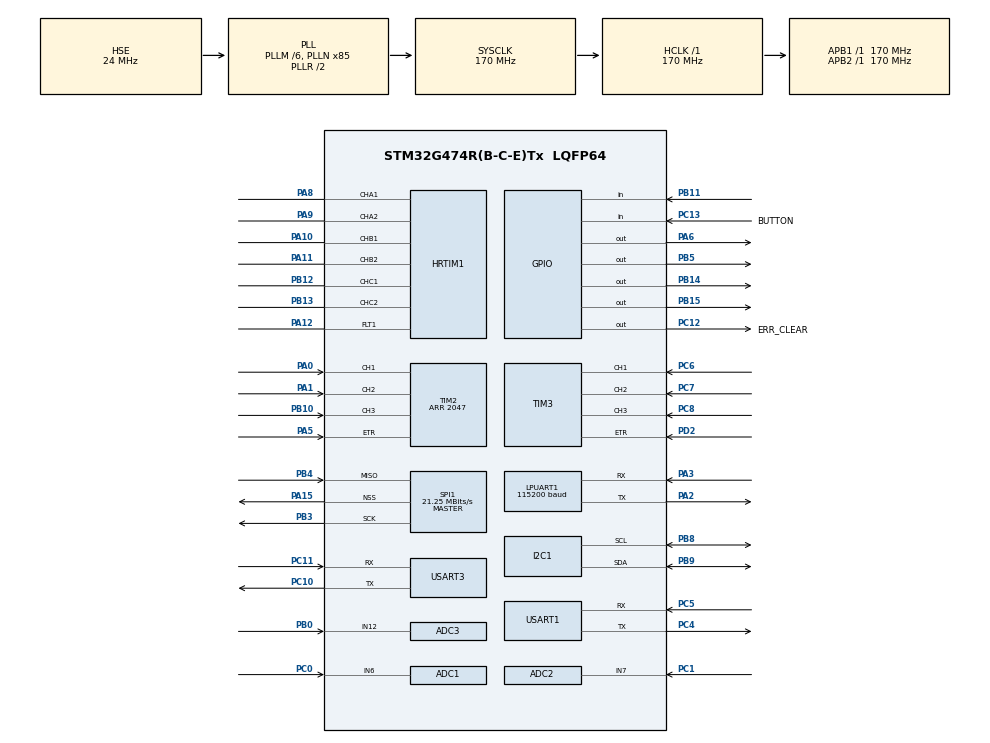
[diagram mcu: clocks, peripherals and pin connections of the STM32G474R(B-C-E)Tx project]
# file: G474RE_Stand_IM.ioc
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ADC1.Channel-0\#ChannelRegularConversion=ADC_CHANNEL_6
ADC1.DMAContinuousRequests=ENABLE
ADC1.ExternalTrigConv=ADC_EXTERNALTRIG_HRTIM_TRG1
ADC1.NbrOfConversionFlag=1
ADC1.Offset-0\#ChannelRegularConversion=2047
ADC1.OffsetNumber-0\#ChannelRegularConversion=ADC_OFFSET_1
ADC1.Rank-0\#ChannelRegularConversion=1
ADC1.SamplingTime-0\#ChannelRegularConversion=ADC_SAMPLETIME_47CYCLES_5
ADC1.master=1
ADC2.Channel-0\#ChannelRegularConversion=ADC_CHANNEL_7
ADC2.DMAContinuousRequests=ENABLE
ADC2.ExternalTrigConv=ADC_EXTERNALTRIG_HRTIM_TRG1
ADC2.NbrOfConversionFlag=1
ADC2.Offset-0\#ChannelRegularConversion=2047
ADC2.OffsetNumber-0\#ChannelRegularConversion=ADC_OFFSET_1
ADC2.Rank-0\#ChannelRegularConversion=1
ADC2.SamplingTime-0\#ChannelRegularConversion=ADC_SAMPLETIME_47CYCLES_5
ADC3.Channel-0\#ChannelRegularConversion=ADC_CHANNEL_12
ADC3.DMAContinuousRequests=ENABLE
ADC3.ExternalTrigConv=ADC_EXTERNALTRIG_HRTIM_TRG1
ADC3.NbrOfConversionFlag=1
ADC3.OffsetNumber-0\#ChannelRegularConversion=ADC_OFFSET_NONE
ADC3.Rank-0\#ChannelRegularConversion=1
ADC3.SamplingTime-0\#ChannelRegularConversion=ADC_SAMPLETIME_47CYCLES_5
ADC3.master=1
Dma.ADC1.0.Direction=DMA_PERIPH_TO_MEMORY
Dma.ADC1.0.EventEnable=DISABLE
Dma.ADC1.0.Instance=DMA1_Channel1
Dma.ADC1.0.MemDataAlignment=DMA_MDATAALIGN_HALFWORD
Dma.ADC1.0.MemInc=DMA_MINC_ENABLE
Dma.ADC1.0.Mode=DMA_CIRCULAR
Dma.ADC1.0.PeriphDataAlignment=DMA_PDATAALIGN_HALFWORD
Dma.ADC1.0.PeriphInc=DMA_PINC_DISABLE
Dma.ADC1.0.Polarity=HAL_DMAMUX_REQ_GEN_RISING
Dma.ADC1.0.Priority=DMA_PRIORITY_LOW
Dma.ADC1.0.RequestNumber=1
Dma.ADC1.0.SignalID=NONE
Dma.ADC1.0.SyncEnable=DISABLE
Dma.ADC1.0.SyncPolarity=HAL_DMAMUX_SYNC_NO_EVENT
Dma.ADC1.0.SyncRequestNumber=1
Dma.ADC1.0.SyncSignalID=NONE
Dma.ADC2.1.Direction=DMA_PERIPH_TO_MEMORY
Dma.ADC2.1.EventEnable=DISABLE
Dma.ADC2.1.Instance=DMA1_Channel2
Dma.ADC2.1.MemDataAlignment=DMA_MDATAALIGN_HALFWORD
Dma.ADC2.1.MemInc=DMA_MINC_ENABLE
Dma.ADC2.1.Mode=DMA_CIRCULAR
Dma.ADC2.1.PeriphDataAlignment=DMA_PDATAALIGN_HALFWORD
Dma.ADC2.1.PeriphInc=DMA_PINC_DISABLE
Dma.ADC2.1.Polarity=HAL_DMAMUX_REQ_GEN_RISING
Dma.ADC2.1.Priority=DMA_PRIORITY_LOW
Dma.ADC2.1.RequestNumber=1
Dma.ADC2.1.SignalID=NONE
Dma.ADC2.1.SyncEnable=DISABLE
Dma.ADC2.1.SyncPolarity=HAL_DMAMUX_SYNC_NO_EVENT
Dma.ADC2.1.SyncRequestNumber=1
Dma.ADC2.1.SyncSignalID=NONE
Dma.ADC3.2.Direction=DMA_PERIPH_TO_MEMORY
Dma.ADC3.2.EventEnable=DISABLE
Dma.ADC3.2.Instance=DMA1_Channel3
Dma.ADC3.2.MemDataAlignment=DMA_MDATAALIGN_HALFWORD
Dma.ADC3.2.MemInc=DMA_MINC_ENABLE
Dma.ADC3.2.Mode=DMA_CIRCULAR
Dma.ADC3.2.PeriphDataAlignment=DMA_PDATAALIGN_HALFWORD
Dma.ADC3.2.PeriphInc=DMA_PINC_DISABLE
Dma.ADC3.2.Polarity=HAL_DMAMUX_REQ_GEN_RISING
Dma.ADC3.2.Priority=DMA_PRIORITY_LOW
Dma.ADC3.2.RequestNumber=1
Dma.ADC3.2.SignalID=NONE
Dma.ADC3.2.SyncEnable=DISABLE
Dma.ADC3.2.SyncPolarity=HAL_DMAMUX_SYNC_NO_EVENT
Dma.ADC3.2.SyncRequestNumber=1
Dma.ADC3.2.SyncSignalID=NONE
Dma.Request0=ADC1
Dma.Request1=ADC2
Dma.Request2=ADC3
HRTIM1.ADCTrigger1_Source1=HRTIM_ADCTRIGGEREVENT13_MASTER_CMP1
HRTIM1.ADCTrigger_Id1=HRTIM_ADCTRIGGER_1
HRTIM1.BlankingSourceFaultLine1=HRTIM_FAULTBLANKINGMODE_MOVING
HRTIM1.CompareUnit1-MasterTimer=HRTIM_COMPAREUNIT_1
HRTIM1.CompareUnit1-Output_TA1TA2=HRTIM_COMPAREUNIT_1
HRTIM1.CompareUnit1-Output_TB1TB2=HRTIM_COMPAREUNIT_1
HRTIM1.CompareUnit1-Output_TC1TC2=HRTIM_COMPAREUNIT_1
HRTIM1.CompareUnit3-Output_TA1TA2=__NULL
HRTIM1.CompareValue1-MasterTimer=(HRTIM_PERIOD/2)
HRTIM1.CompareValue1-Output_TA1TA2=(HRTIM_PERIOD/2)
HRTIM1.CompareValue1-Output_TB1TB2=HRTIM_PERIOD/2
HRTIM1.CompareValue1-Output_TC1TC2=(HRTIM_PERIOD/2)
HRTIM1.CounterFaultLine1=0
HRTIM1.DeadTimeInsertion-Output_TA1TA2=HRTIM_TIMDEADTIMEINSERTION_ENABLED
HRTIM1.DeadTimeInsertion-Output_TB1TB2=HRTIM_TIMDEADTIMEINSERTION_ENABLED
HRTIM1.DeadTimeInsertion-Output_TC1TC2=HRTIM_TIMDEADTIMEINSERTION_ENABLED
HRTIM1.Enable_FaultLine1=HRTIM_FAULTMODECTL_DISABLED
HRTIM1.FallingValue-Output_TA1TA2=HRTIM_DEADTIME
HRTIM1.FallingValue-Output_TB1TB2=HRTIM_DEADTIME
HRTIM1.FallingValue-Output_TC1TC2=HRTIM_DEADTIME
HRTIM1.FaultEnable_Source1-Output_TA1TA2=HRTIM_TIMFAULTENABLE_FAULT1
HRTIM1.FaultEnable_Source1-Output_TB1TB2=HRTIM_TIMFAULTENABLE_FAULT1
HRTIM1.FaultEnable_Source1-Output_TC1TC2=HRTIM_TIMFAULTENABLE_FAULT1
HRTIM1.FaultLevel1-Output_TA1TA2=HRTIM_OUTPUTFAULTLEVEL_INACTIVE
HRTIM1.FaultLevel1-Output_TB1TB2=HRTIM_OUTPUTFAULTLEVEL_INACTIVE
HRTIM1.FaultLevel1-Output_TC1TC2=HRTIM_OUTPUTFAULTLEVEL_INACTIVE
HRTIM1.FaultLevel2-Output_TA1TA2=HRTIM_OUTPUTFAULTLEVEL_INACTIVE
HRTIM1.FaultLevel2-Output_TB1TB2=HRTIM_OUTPUTFAULTLEVEL_INACTIVE
HRTIM1.FaultLevel2-Output_TC1TC2=HRTIM_OUTPUTFAULTLEVEL_INACTIVE
HRTIM1.Filter_FaultLine1=HRTIM_FAULTFILTER_3
HRTIM1.InterruptRequests1_Master=HRTIM_MASTER_IT_MCMP1
HRTIM1.NumberADCTriggerSource1=1
HRTIM1.NumberFaultEnable-Output_TA1TA2=1
HRTIM1.NumberFaultEnable-Output_TB1TB2=1
HRTIM1.NumberFaultEnable-Output_TC1TC2=1
HRTIM1.NumberInterruptRequests_Master-MasterTimer=1
HRTIM1.NumberResetSource1-Output_TA1TA2=1
HRTIM1.NumberResetSource1-Output_TB1TB2=1
HRTIM1.NumberResetSource1-Output_TC1TC2=1
HRTIM1.NumberResetTrigger-Output_TA1TA2=1
HRTIM1.NumberResetTrigger-Output_TB1TB2=1
HRTIM1.NumberResetTrigger-Output_TC1TC2=1
HRTIM1.NumberSetSource1-Output_TA1TA2=0
HRTIM1.NumberSetSource1-Output_TB1TB2=0
HRTIM1.NumberSetSource1-Output_TC1TC2=0
HRTIM1.Periode_MASTER=HRTIM_PERIOD
HRTIM1.Periode_TA=HRTIM_PERIOD
HRTIM1.Periode_TB=HRTIM_PERIOD
HRTIM1.Periode_TC=HRTIM_PERIOD
HRTIM1.PreloadEnable-MasterTimer=HRTIM_PRELOAD_ENABLED
HRTIM1.PreloadEnable-Output_TA1TA2=HRTIM_PRELOAD_ENABLED
HRTIM1.PreloadEnable-Output_TB1TB2=HRTIM_PRELOAD_ENABLED
HRTIM1.PreloadEnable-Output_TC1TC2=HRTIM_PRELOAD_ENABLED
HRTIM1.PrescalerDead-Output_TA1TA2=HRTIM_TIMDEADTIME_PRESCALERRATIO_DIV1
HRTIM1.PrescalerDead-Output_TB1TB2=HRTIM_TIMDEADTIME_PRESCALERRATIO_DIV1
HRTIM1.PrescalerDead-Output_TC1TC2=HRTIM_TIMDEADTIME_PRESCALERRATIO_DIV1
HRTIM1.PrescalerRatio_MASTER=HRTIM_PRESCALERRATIO_MUL2
HRTIM1.PrescalerRatio_TA=HRTIM_PRESCALERRATIO_MUL4
HRTIM1.PrescalerRatio_TB=HRTIM_PRESCALERRATIO_MUL4
HRTIM1.PrescalerRatio_TC=HRTIM_PRESCALERRATIO_MUL4
HRTIM1.RepetitionUpdate-MasterTimer=HRTIM_UPDATEONREPETITION_ENABLED
HRTIM1.ResetOutput1_Source1-Output_TA1TA2=HRTIM_OUTPUTRESET_TIMCMP1
HRTIM1.ResetOutput1_Source1-Output_TB1TB2=HRTIM_OUTPUTRESET_TIMCMP1
HRTIM1.ResetOutput1_Source1-Output_TC1TC2=HRTIM_OUTPUTRESET_TIMCMP1
HRTIM1.ResetTrigger1-Output_TA1TA2=HRTIM_TIMRESETTRIGGER_MASTER_PER
HRTIM1.ResetTrigger1-Output_TB1TB2=HRTIM_TIMRESETTRIGGER_MASTER_PER
HRTIM1.ResetTrigger1-Output_TC1TC2=HRTIM_TIMRESETTRIGGER_MASTER_PER
HRTIM1.ResetUpdate-Output_TA1TA2=HRTIM_TIMUPDATEONRESET_ENABLED
HRTIM1.ResetUpdate-Output_TB1TB2=HRTIM_TIMUPDATEONRESET_ENABLED
HRTIM1.ResetUpdate-Output_TC1TC2=HRTIM_TIMUPDATEONRESET_ENABLED
HRTIM1.RisingValue-Output_TA1TA2=HRTIM_DEADTIME
HRTIM1.RisingValue-Output_TB1TB2=HRTIM_DEADTIME
HRTIM1.RisingValue-Output_TC1TC2=HRTIM_DEADTIME
HRTIM1.UpDownMode-Output_TA1TA2=HRTIM_TIMERUPDOWNMODE_UPDOWN
HRTIM1.UpDownMode-Output_TB1TB2=HRTIM_TIMERUPDOWNMODE_UPDOWN
HRTIM1.UpDownMode-Output_TC1TC2=HRTIM_TIMERUPDOWNMODE_UPDOWN
I2C1.Timing=0x30A0A7FB
IWDG.Reload=4095
LPUART1.BaudRate=115200
LPUART1.FIFOMode=UART_FIFOMODE_ENABLE
LPUART1.RXFIFOThreshold=UART_RXFIFO_THRESHOLD_1_2
LPUART1.TXFIFOThreshold=UART_TXFIFO_THRESHOLD_1_2
Mcu.Family=STM32G4
Mcu.Name=STM32G474R(B-C-E)Tx
Mcu.Package=LQFP64
Mcu.UserConstants=HRTIM_PERIOD_20kHz,(17000);HRTIM_PERIOD_10kHz,(34000);HRTIM_PERIOD,HRTIM_PERIOD_20kHz;HRTIM_PERIOD_16kHz,(21250);HRTIM_DEADTIME_1us,(170);HRTIM_DEADTIME_500ns,(85);HRTIM_DEADTIME_800ns,(136);HRTIM_DEADTIME,HRTIM_DEADTIME_1us
NVIC.DMA1_Channel1_IRQn=true\:10\:0\:true\:false\:true\:true\:false\:true
NVIC.HRTIM1_Master_IRQn=true\:8\:0\:true\:false\:true\:true\:false\:true
NVIC.PriorityGroup=NVIC_PRIORITYGROUP_4
NVIC.SPI1_IRQn=true\:6\:0\:true\:false\:true\:true\:false\:true
PA0.Signal=S_TIM2_CH1
PA1.Signal=S_TIM2_CH2
PA10.GPIO_PuPd=GPIO_NOPULL
PA10.Mode=Output_TB1TB2
PA10.Signal=HRTIM1_CHB1
PA11.Mode=Output_TB1TB2
PA11.Signal=HRTIM1_CHB2
PA12.GPIO_PuPd=GPIO_PULLDOWN
PA12.Mode=Fault_Enable1
PA12.Signal=HRTIM1_FLT1
PA13.Mode=Serial_Wire
PA13.Signal=SYS_JTMS-SWDIO
PA14.Mode=Serial_Wire
PA14.Signal=SYS_JTCK-SWCLK
PA15.Mode=NSS_Signal_Hard_Output
PA15.Signal=SPI1_NSS
PA2.Mode=Asynchronous
PA2.Signal=LPUART1_TX
PA3.Mode=Asynchronous
PA3.Signal=LPUART1_RX
PA5.Signal=S_TIM2_ETR
PA6.Signal=GPIO_Output
PA8.GPIO_PuPd=GPIO_NOPULL
PA8.Mode=Output_TA1TA2
PA8.Signal=HRTIM1_CHA1
PA9.GPIO_PuPd=GPIO_NOPULL
PA9.Mode=Output_TA1TA2
PA9.Signal=HRTIM1_CHA2
PB0.Mode=IN12-Single-Ended
PB0.Signal=ADC3_IN12
PB10.Signal=S_TIM2_CH3
PB11.Signal=GPIO_Input
PB12.Mode=Output_TC1TC2
PB12.Signal=HRTIM1_CHC1
PB13.Mode=Output_TC1TC2
PB13.Signal=HRTIM1_CHC2
PB14.Signal=GPIO_Output
PB15.Signal=GPIO_Output
PB3.Mode=RX_Only_Simplex_Unidirect_Master
PB3.Signal=SPI1_SCK
PB4.Mode=RX_Only_Simplex_Unidirect_Master
PB4.Signal=SPI1_MISO
PB5.Signal=GPIO_Output
PB8-BOOT0.Mode=I2C
PB8-BOOT0.Signal=I2C1_SCL
PB9.Mode=I2C
PB9.Signal=I2C1_SDA
PC0.Mode=IN6-Single-Ended
PC0.Signal=ADC1_IN6
PC1.Mode=IN7-Single-Ended
PC1.Signal=ADC2_IN7
PC10.Mode=Asynchronous
PC10.Signal=USART3_TX
PC11.Mode=Asynchronous
PC11.Signal=USART3_RX
PC12.GPIO_Label=ERR_CLEAR
PC12.Signal=GPIO_Output
PC13.GPIO_Label=BUTTON
PC13.Signal=GPIO_Input
PC14-OSC32_IN.Mode=LSE-External-Oscillator
PC14-OSC32_IN.Signal=RCC_OSC32_IN
PC15-OSC32_OUT.Mode=LSE-External-Oscillator
PC15-OSC32_OUT.Signal=RCC_OSC32_OUT
PC4.Mode=Asynchronous
PC4.Signal=USART1_TX
PC5.Mode=Asynchronous
PC5.Signal=USART1_RX
PC6.Signal=S_TIM3_CH1
PC7.Signal=S_TIM3_CH2
PC8.Signal=S_TIM3_CH3
PD2.Signal=S_TIM3_ETR
PF0-OSC_IN.Mode=HSE-External-Oscillator
PF0-OSC_IN.Signal=RCC_OSC_IN
PF1-OSC_OUT.Mode=HSE-External-Oscillator
PF1-OSC_OUT.Signal=RCC_OSC_OUT
ProjectManager.HeapSize=0x200
ProjectManager.StackSize=0x400
ProjectManager.TargetToolchain=STM32CubeIDE
RCC.ADC12Freq_Value=170000000
RCC.ADC345Freq_Value=170000000
RCC.AHBFreq_Value=170000000
RCC.APB1Freq_Value=170000000
RCC.APB1TimFreq_Value=170000000
RCC.APB2Freq_Value=170000000
RCC.APB2TimFreq_Value=170000000
RCC.CortexFreq_Value=170000000
RCC.EXTERNAL_CLOCK_VALUE=12288000
RCC.HCLKFreq_Value=170000000
RCC.HSE_VALUE=24000000
RCC.HSI48_VALUE=48000000
RCC.HSI_VALUE=16000000
RCC.PLLM=RCC_PLLM_DIV6
RCC.PLLN=85
RCC.PLLSourceVirtual=RCC_PLLSOURCE_HSE
RCC.SYSCLKFreq_VALUE=170000000
RCC.SYSCLKSource=RCC_SYSCLKSOURCE_PLLCLK
RCC.USBFreq_Value=170000000
RCC.VCOOutputFreq_Value=340000000
SH.S_TIM2_CH1.0=TIM2_CH1,Encoder_Interface_w_index
SH.S_TIM2_CH2.0=TIM2_CH2,Encoder_Interface_w_index
SH.S_TIM2_CH3.0=TIM2_CH3,Input_Capture3_from_TI3
SH.S_TIM2_ETR.0=TIM2_ETR,Encoder_Interface_w_index
SH.S_TIM3_CH1.0=TIM3_CH1,Encoder_Interface_w_index
SH.S_TIM3_CH2.0=TIM3_CH2,Encoder_Interface_w_index
SH.S_TIM3_CH3.0=TIM3_CH3,Input_Capture3_from_TI3
SH.S_TIM3_ETR.0=TIM3_ETR,Encoder_Interface_w_index
SPI1.BaudRatePrescaler=SPI_BAUDRATEPRESCALER_8
SPI1.CalculateBaudRate=21.25 MBits/s
SPI1.DataSize=SPI_DATASIZE_16BIT
SPI1.Direction=SPI_DIRECTION_2LINES_RXONLY
SPI1.Mode=SPI_MODE_MASTER
SPI1.NSSPMode=SPI_NSS_PULSE_ENABLE
SPI1.VirtualNSS=VM_NSSHARD
SPI1.VirtualType=VM_MASTER
TIM2.Channel-Input_Capture3_from_TI3=TIM_CHANNEL_3
TIM2.IndexPosition=TIM_ENCODERINDEX_POSITION_10
TIM2.PeriodNoDither=2047
TIM3.Channel-Input_Capture3_from_TI3=TIM_CHANNEL_3
USART1.VirtualMode-Asynchronous=VM_ASYNC
USART3.VirtualMode-Asynchronous=VM_ASYNC
VP_HRTIM1_VS_hrtimMasterTimerNoOutput.Mode=MasterTimer
VP_IWDG_VS_IWDG.Mode=IWDG_Activate
VP_SYS_VS_DBSignals.Mode=DisableDeadBatterySignals
board=custom

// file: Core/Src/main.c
/* USER CODE BEGIN Header */
/**
  ******************************************************************************
  * @file           : main.c
  * @brief          : Main program body
  ******************************************************************************
  * @attention
  *
  * Copyright (c) 2023 STMicroelectronics.
  * All rights reserved.
  *
  * This software is licensed under terms that can be found in the LICENSE file
  * in the root directory of this software component.
  * If no LICENSE file comes with this software, it is provided AS-IS.
  *
  ******************************************************************************
  */
/* USER CODE END Header */
#include "main.h"

ADC_HandleTypeDef hadc1;
ADC_HandleTypeDef hadc2;
ADC_HandleTypeDef hadc3;
DMA_HandleTypeDef hdma_adc1;
DMA_HandleTypeDef hdma_adc2;
DMA_HandleTypeDef hdma_adc3;

HRTIM_HandleTypeDef hhrtim1;

I2C_HandleTypeDef hi2c1;

IWDG_HandleTypeDef hiwdg;

UART_HandleTypeDef hlpuart1;
UART_HandleTypeDef huart1;
UART_HandleTypeDef huart3;

TIM_HandleTypeDef htim2;
TIM_HandleTypeDef htim3;

void SystemClock_Config(void);
static void MX_GPIO_Init(void);
static void MX_DMA_Init(void);
static void MX_HRTIM1_Init(void);
static void MX_I2C1_Init(void);
static void MX_SPI1_Init(void);
static void MX_TIM2_Init(void);
static void MX_TIM3_Init(void);
static void MX_USART3_UART_Init(void);
static void MX_LPUART1_UART_Init(void);
static void MX_USART1_UART_Init(void);
static void MX_ADC3_Init(void);
static void MX_ADC1_Init(void);
static void MX_ADC2_Init(void);
static void MX_IWDG_Init(void);

int main(void)
{

  /* MCU Configuration--------------------------------------------------------*/

  /* Reset of all peripherals, Initializes the Flash interface and the Systick. */
  HAL_Init();

  /* USER CODE BEGIN Init */
  stand_im_init_1();
  /* USER CODE END Init */

  /* Configure the system clock */
  SystemClock_Config();

  /* Initialize all configured peripherals */
  MX_GPIO_Init();
  MX_DMA_Init();
  MX_HRTIM1_Init();
  MX_I2C1_Init();
  MX_SPI1_Init();
  MX_TIM2_Init();
  MX_TIM3_Init();
  MX_USART3_UART_Init();
  MX_LPUART1_UART_Init();
  MX_USART1_UART_Init();
  MX_ADC3_Init();
  MX_ADC1_Init();
  MX_ADC2_Init();
  MX_IWDG_Init();
  /* USER CODE BEGIN 2 */
  stand_im_init_2();
  /* USER CODE END 2 */

  /* Infinite loop */
  /* USER CODE BEGIN WHILE */
  while (1)
  {
    stand_im_loop();
    /* USER CODE END WHILE */

  }
}

void SystemClock_Config(void)
{
  RCC_OscInitTypeDef RCC_OscInitStruct = {0};
  RCC_ClkInitTypeDef RCC_ClkInitStruct = {0};

  /** Configure the main internal regulator output voltage
  */
  HAL_PWREx_ControlVoltageScaling(PWR_REGULATOR_VOLTAGE_SCALE1_BOOST);

  /** Initializes the RCC Oscillators according to the specified parameters
  * in the RCC_OscInitTypeDef structure.
  */
  RCC_OscInitStruct.OscillatorType = RCC_OSCILLATORTYPE_LSI|RCC_OSCILLATORTYPE_HSE;
  RCC_OscInitStruct.HSEState = RCC_HSE_ON;
  RCC_OscInitStruct.LSIState = RCC_LSI_ON;
  RCC_OscInitStruct.PLL.PLLState = RCC_PLL_ON;
  RCC_OscInitStruct.PLL.PLLSource = RCC_PLLSOURCE_HSE;
  RCC_OscInitStruct.PLL.PLLM = RCC_PLLM_DIV6;
  RCC_OscInitStruct.PLL.PLLN = 85;
  RCC_OscInitStruct.PLL.PLLP = RCC_PLLP_DIV2;
  RCC_OscInitStruct.PLL.PLLQ = RCC_PLLQ_DIV2;
  RCC_OscInitStruct.PLL.PLLR = RCC_PLLR_DIV2;
  if (HAL_RCC_OscConfig(&RCC_OscInitStruct) != HAL_OK)
  {
    Error_Handler();
  }

  /** Initializes the CPU, AHB and APB buses clocks
  */
  RCC_ClkInitStruct.ClockType = RCC_CLOCKTYPE_HCLK|RCC_CLOCKTYPE_SYSCLK
                              |RCC_CLOCKTYPE_PCLK1|RCC_CLOCKTYPE_PCLK2;
  RCC_ClkInitStruct.SYSCLKSource = RCC_SYSCLKSOURCE_PLLCLK;
  RCC_ClkInitStruct.AHBCLKDivider = RCC_SYSCLK_DIV1;
  RCC_ClkInitStruct.APB1CLKDivider = RCC_HCLK_DIV1;
  RCC_ClkInitStruct.APB2CLKDivider = RCC_HCLK_DIV1;

  if (HAL_RCC_ClockConfig(&RCC_ClkInitStruct, FLASH_LATENCY_4) != HAL_OK)
  {
    Error_Handler();
  }
}

static void MX_ADC1_Init(void)
{

  ADC_MultiModeTypeDef multimode = {0};
  ADC_ChannelConfTypeDef sConfig = {0};

  /** Common config
  */
  hadc1.Instance = ADC1;
  hadc1.Init.ClockPrescaler = ADC_CLOCK_SYNC_PCLK_DIV4;
  hadc1.Init.Resolution = ADC_RESOLUTION_12B;
  hadc1.Init.DataAlign = ADC_DATAALIGN_RIGHT;
  hadc1.Init.GainCompensation = 0;
  hadc1.Init.ScanConvMode = ADC_SCAN_DISABLE;
  hadc1.Init.EOCSelection = ADC_EOC_SINGLE_CONV;
  hadc1.Init.LowPowerAutoWait = DISABLE;
  hadc1.Init.ContinuousConvMode = DISABLE;
  hadc1.Init.NbrOfConversion = 1;
  hadc1.Init.DiscontinuousConvMode = DISABLE;
  hadc1.Init.ExternalTrigConv = ADC_EXTERNALTRIG_HRTIM_TRG1;
  hadc1.Init.ExternalTrigConvEdge = ADC_EXTERNALTRIGCONVEDGE_RISING;
  hadc1.Init.DMAContinuousRequests = ENABLE;
  hadc1.Init.Overrun = ADC_OVR_DATA_PRESERVED;
  hadc1.Init.OversamplingMode = DISABLE;
  if (HAL_ADC_Init(&hadc1) != HAL_OK)
  {
    Error_Handler();
  }

  /** Configure the ADC multi-mode
  */
  multimode.Mode = ADC_MODE_INDEPENDENT;
  if (HAL_ADCEx_MultiModeConfigChannel(&hadc1, &multimode) != HAL_OK)
  {
    Error_Handler();
  }

  /** Configure Regular Channel
  */
  sConfig.Channel = ADC_CHANNEL_6;
  sConfig.Rank = ADC_REGULAR_RANK_1;
  sConfig.SamplingTime = ADC_SAMPLETIME_47CYCLES_5;
  sConfig.SingleDiff = ADC_SINGLE_ENDED;
  sConfig.OffsetNumber = ADC_OFFSET_1;
  sConfig.Offset = 2047;
  sConfig.OffsetSign = ADC_OFFSET_SIGN_NEGATIVE;
  sConfig.OffsetSaturation = DISABLE;
  if (HAL_ADC_ConfigChannel(&hadc1, &sConfig) != HAL_OK)
  {
    Error_Handler();
  }

}

static void MX_ADC2_Init(void)
{

  ADC_ChannelConfTypeDef sConfig = {0};

  /** Common config
  */
  hadc2.Instance = ADC2;
  hadc2.Init.ClockPrescaler = ADC_CLOCK_SYNC_PCLK_DIV4;
  hadc2.Init.Resolution = ADC_RESOLUTION_12B;
  hadc2.Init.DataAlign = ADC_DATAALIGN_RIGHT;
  hadc2.Init.GainCompensation = 0;
  hadc2.Init.ScanConvMode = ADC_SCAN_DISABLE;
  hadc2.Init.EOCSelection = ADC_EOC_SINGLE_CONV;
  hadc2.Init.LowPowerAutoWait = DISABLE;
  hadc2.Init.ContinuousConvMode = DISABLE;
  hadc2.Init.NbrOfConversion = 1;
  hadc2.Init.DiscontinuousConvMode = DISABLE;
  hadc2.Init.ExternalTrigConv = ADC_EXTERNALTRIG_HRTIM_TRG1;
  hadc2.Init.ExternalTrigConvEdge = ADC_EXTERNALTRIGCONVEDGE_RISING;
  hadc2.Init.DMAContinuousRequests = ENABLE;
  hadc2.Init.Overrun = ADC_OVR_DATA_PRESERVED;
  hadc2.Init.OversamplingMode = DISABLE;
  if (HAL_ADC_Init(&hadc2) != HAL_OK)
  {
    Error_Handler();
  }

  /** Configure Regular Channel
  */
  sConfig.Channel = ADC_CHANNEL_7;
  sConfig.Rank = ADC_REGULAR_RANK_1;
  sConfig.SamplingTime = ADC_SAMPLETIME_47CYCLES_5;
  sConfig.SingleDiff = ADC_SINGLE_ENDED;
  sConfig.OffsetNumber = ADC_OFFSET_1;
  sConfig.Offset = 2047;
  sConfig.OffsetSign = ADC_OFFSET_SIGN_NEGATIVE;
  sConfig.OffsetSaturation = DISABLE;
  if (HAL_ADC_ConfigChannel(&hadc2, &sConfig) != HAL_OK)
  {
    Error_Handler();
  }

}

static void MX_ADC3_Init(void)
{

  ADC_MultiModeTypeDef multimode = {0};
  ADC_ChannelConfTypeDef sConfig = {0};

  /** Common config
  */
  hadc3.Instance = ADC3;
  hadc3.Init.ClockPrescaler = ADC_CLOCK_SYNC_PCLK_DIV4;
  hadc3.Init.Resolution = ADC_RESOLUTION_12B;
  hadc3.Init.DataAlign = ADC_DATAALIGN_RIGHT;
  hadc3.Init.GainCompensation = 0;
  hadc3.Init.ScanConvMode = ADC_SCAN_DISABLE;
  hadc3.Init.EOCSelection = ADC_EOC_SINGLE_CONV;
  hadc3.Init.LowPowerAutoWait = DISABLE;
  hadc3.Init.ContinuousConvMode = DISABLE;
  hadc3.Init.NbrOfConversion = 1;
  hadc3.Init.DiscontinuousConvMode = DISABLE;
  hadc3.Init.ExternalTrigConv = ADC_EXTERNALTRIG_HRTIM_TRG1;
  hadc3.Init.ExternalTrigConvEdge = ADC_EXTERNALTRIGCONVEDGE_RISING;
  hadc3.Init.DMAContinuousRequests = ENABLE;
  hadc3.Init.Overrun = ADC_OVR_DATA_PRESERVED;
  hadc3.Init.OversamplingMode = DISABLE;
  if (HAL_ADC_Init(&hadc3) != HAL_OK)
  {
    Error_Handler();
  }

  /** Configure the ADC multi-mode
  */
  multimode.Mode = ADC_MODE_INDEPENDENT;
  if (HAL_ADCEx_MultiModeConfigChannel(&hadc3, &multimode) != HAL_OK)
  {
    Error_Handler();
  }

  /** Configure Regular Channel
  */
  sConfig.Channel = ADC_CHANNEL_12;
  sConfig.Rank = ADC_REGULAR_RANK_1;
  sConfig.SamplingTime = ADC_SAMPLETIME_47CYCLES_5;
  sConfig.SingleDiff = ADC_SINGLE_ENDED;
  sConfig.OffsetNumber = ADC_OFFSET_NONE;
  sConfig.Offset = 0;
  if (HAL_ADC_ConfigChannel(&hadc3, &sConfig) != HAL_OK)
  {
    Error_Handler();
  }

}

static void MX_HRTIM1_Init(void)
{

  HRTIM_FaultCfgTypeDef pFaultCfg = {0};
  HRTIM_FaultBlankingCfgTypeDef pFaultBlkCfg = {0};
  HRTIM_ADCTriggerCfgTypeDef pADCTriggerCfg = {0};
  HRTIM_TimeBaseCfgTypeDef pTimeBaseCfg = {0};
  HRTIM_TimerCfgTypeDef pTimerCfg = {0};
  HRTIM_CompareCfgTypeDef pCompareCfg = {0};
  HRTIM_TimerCtlTypeDef pTimerCtl = {0};
  HRTIM_DeadTimeCfgTypeDef pDeadTimeCfg = {0};
  HRTIM_OutputCfgTypeDef pOutputCfg = {0};

  hhrtim1.Instance = HRTIM1;
  hhrtim1.Init.HRTIMInterruptResquests = HRTIM_IT_NONE;
  hhrtim1.Init.SyncOptions = HRTIM_SYNCOPTION_NONE;
  if (HAL_HRTIM_Init(&hhrtim1) != HAL_OK)
  {
    Error_Handler();
  }
  if (HAL_HRTIM_DLLCalibrationStart(&hhrtim1, HRTIM_CALIBRATIONRATE_3) != HAL_OK)
  {
    Error_Handler();
  }
  if (HAL_HRTIM_PollForDLLCalibration(&hhrtim1, 10) != HAL_OK)
  {
    Error_Handler();
  }
  if (HAL_HRTIM_FaultPrescalerConfig(&hhrtim1, HRTIM_FAULTPRESCALER_DIV1) != HAL_OK)
  {
    Error_Handler();
  }
  pFaultCfg.Source = HRTIM_FAULTSOURCE_DIGITALINPUT;
  pFaultCfg.Polarity = HRTIM_FAULTPOLARITY_HIGH;
  pFaultCfg.Filter = HRTIM_FAULTFILTER_3;
  pFaultCfg.Lock = HRTIM_FAULTLOCK_READWRITE;
  if (HAL_HRTIM_FaultConfig(&hhrtim1, HRTIM_FAULT_1, &pFaultCfg) != HAL_OK)
  {
    Error_Handler();
  }
  pFaultBlkCfg.Threshold = 0;
  pFaultBlkCfg.ResetMode = HRTIM_FAULTCOUNTERRST_UNCONDITIONAL;
  pFaultBlkCfg.BlankingSource = HRTIM_FAULTBLANKINGMODE_MOVING;
  if (HAL_HRTIM_FaultCounterConfig(&hhrtim1, HRTIM_FAULT_1, &pFaultBlkCfg) != HAL_OK)
  {
    Error_Handler();
  }
  if (HAL_HRTIM_FaultBlankingConfigAndEnable(&hhrtim1, HRTIM_FAULT_1, &pFaultBlkCfg) != HAL_OK)
  {
    Error_Handler();
  }
  HAL_HRTIM_FaultModeCtl(&hhrtim1, HRTIM_FAULT_1, HRTIM_FAULTMODECTL_DISABLED);
  pADCTriggerCfg.UpdateSource = HRTIM_ADCTRIGGERUPDATE_MASTER;
  pADCTriggerCfg.Trigger = HRTIM_ADCTRIGGEREVENT13_MASTER_CMP1;
  if (HAL_HRTIM_ADCTriggerConfig(&hhrtim1, HRTIM_ADCTRIGGER_1, &pADCTriggerCfg) != HAL_OK)
  {
    Error_Handler();
  }
  if (HAL_HRTIM_ADCPostScalerConfig(&hhrtim1, HRTIM_ADCTRIGGER_1, 0x0) != HAL_OK)
  {
    Error_Handler();
  }
  pTimeBaseCfg.Period = HRTIM_PERIOD;
  pTimeBaseCfg.RepetitionCounter = 0x00;
  pTimeBaseCfg.PrescalerRatio = HRTIM_PRESCALERRATIO_MUL2;
  pTimeBaseCfg.Mode = HRTIM_MODE_CONTINUOUS;
  if (HAL_HRTIM_TimeBaseConfig(&hhrtim1, HRTIM_TIMERINDEX_MASTER, &pTimeBaseCfg) != HAL_OK)
  {
    Error_Handler();
  }
  pTimerCfg.InterruptRequests = HRTIM_MASTER_IT_MCMP1;
  pTimerCfg.DMARequests = HRTIM_MASTER_DMA_NONE;
  pTimerCfg.DMASrcAddress = 0x0000;
  pTimerCfg.DMADstAddress = 0x0000;
  pTimerCfg.DMASize = 0x1;
  pTimerCfg.HalfModeEnable = HRTIM_HALFMODE_DISABLED;
  pTimerCfg.InterleavedMode = HRTIM_INTERLEAVED_MODE_DISABLED;
  pTimerCfg.StartOnSync = HRTIM_SYNCSTART_DISABLED;
  pTimerCfg.ResetOnSync = HRTIM_SYNCRESET_DISABLED;
  pTimerCfg.DACSynchro = HRTIM_DACSYNC_NONE;
  pTimerCfg.PreloadEnable = HRTIM_PRELOAD_ENABLED;
  pTimerCfg.UpdateGating = HRTIM_UPDATEGATING_INDEPENDENT;
  pTimerCfg.BurstMode = HRTIM_TIMERBURSTMODE_MAINTAINCLOCK;
  pTimerCfg.RepetitionUpdate = HRTIM_UPDATEONREPETITION_ENABLED;
  pTimerCfg.ReSyncUpdate = HRTIM_TIMERESYNC_UPDATE_UNCONDITIONAL;
  if (HAL_HRTIM_WaveformTimerConfig(&hhrtim1, HRTIM_TIMERINDEX_MASTER, &pTimerCfg) != HAL_OK)
  {
    Error_Handler();
  }
  pCompareCfg.CompareValue = (HRTIM_PERIOD/2);
  if (HAL_HRTIM_WaveformCompareConfig(&hhrtim1, HRTIM_TIMERINDEX_MASTER, HRTIM_COMPAREUNIT_1, &pCompareCfg) != HAL_OK)
  {
    Error_Handler();
  }
  pTimeBaseCfg.PrescalerRatio = HRTIM_PRESCALERRATIO_MUL4;
  if (HAL_HRTIM_TimeBaseConfig(&hhrtim1, HRTIM_TIMERINDEX_TIMER_A, &pTimeBaseCfg) != HAL_OK)
  {
    Error_Handler();
  }
  pTimerCtl.UpDownMode = HRTIM_TIMERUPDOWNMODE_UPDOWN;
  pTimerCtl.GreaterCMP1 = HRTIM_TIMERGTCMP1_EQUAL;
  pTimerCtl.DualChannelDacEnable = HRTIM_TIMER_DCDE_DISABLED;
  if (HAL_HRTIM_WaveformTimerControl(&hhrtim1, HRTIM_TIMERINDEX_TIMER_A, &pTimerCtl) != HAL_OK)
  {
    Error_Handler();
  }
  if (HAL_HRTIM_RollOverModeConfig(&hhrtim1, HRTIM_TIMERINDEX_TIMER_A, HRTIM_TIM_FEROM_BOTH|HRTIM_TIM_BMROM_BOTH
                              |HRTIM_TIM_ADROM_BOTH|HRTIM_TIM_OUTROM_BOTH
                              |HRTIM_TIM_ROM_BOTH) != HAL_OK)
  {
    Error_Handler();
  }
  pTimerCfg.InterruptRequests = HRTIM_TIM_IT_NONE;
  pTimerCfg.DMARequests = HRTIM_TIM_DMA_NONE;
  pTimerCfg.RepetitionUpdate = HRTIM_UPDATEONREPETITION_DISABLED;
  pTimerCfg.PushPull = HRTIM_TIMPUSHPULLMODE_DISABLED;
  pTimerCfg.FaultEnable = HRTIM_TIMFAULTENABLE_FAULT1;
  pTimerCfg.FaultLock = HRTIM_TIMFAULTLOCK_READWRITE;
  pTimerCfg.DeadTimeInsertion = HRTIM_TIMDEADTIMEINSERTION_ENABLED;
  pTimerCfg.DelayedProtectionMode = HRTIM_TIMER_A_B_C_DELAYEDPROTECTION_DISABLED;
  pTimerCfg.UpdateTrigger = HRTIM_TIMUPDATETRIGGER_NONE;
  pTimerCfg.ResetTrigger = HRTIM_TIMRESETTRIGGER_MASTER_PER;
  pTimerCfg.ResetUpdate = HRTIM_TIMUPDATEONRESET_ENABLED;
  if (HAL_HRTIM_WaveformTimerConfig(&hhrtim1, HRTIM_TIMERINDEX_TIMER_A, &pTimerCfg) != HAL_OK)
  {
    Error_Handler();
  }
  if (HAL_HRTIM_WaveformTimerConfig(&hhrtim1, HRTIM_TIMERINDEX_TIMER_B, &pTimerCfg) != HAL_OK)
  {
    Error_Handler();
  }
  if (HAL_HRTIM_WaveformTimerConfig(&hhrtim1, HRTIM_TIMERINDEX_TIMER_C, &pTimerCfg) != HAL_OK)
  {
    Error_Handler();
  }
  if (HAL_HRTIM_WaveformCompareConfig(&hhrtim1, HRTIM_TIMERINDEX_TIMER_A, HRTIM_COMPAREUNIT_1, &pCompareCfg) != HAL_OK)
  {
    Error_Handler();
  }
  pDeadTimeCfg.Prescaler = HRTIM_TIMDEADTIME_PRESCALERRATIO_DIV1;
  pDeadTimeCfg.RisingValue = HRTIM_DEADTIME;
  pDeadTimeCfg.RisingSign = HRTIM_TIMDEADTIME_RISINGSIGN_POSITIVE;
  pDeadTimeCfg.RisingLock = HRTIM_TIMDEADTIME_RISINGLOCK_WRITE;
  pDeadTimeCfg.RisingSignLock = HRTIM_TIMDEADTIME_RISINGSIGNLOCK_WRITE;
  pDeadTimeCfg.FallingValue = HRTIM_DEADTIME;
  pDeadTimeCfg.FallingSign = HRTIM_TIMDEADTIME_FALLINGSIGN_POSITIVE;
  pDeadTimeCfg.FallingLock = HRTIM_TIMDEADTIME_FALLINGLOCK_WRITE;
  pDeadTimeCfg.FallingSignLock = HRTIM_TIMDEADTIME_FALLINGSIGNLOCK_WRITE;
  if (HAL_HRTIM_DeadTimeConfig(&hhrtim1, HRTIM_TIMERINDEX_TIMER_A, &pDeadTimeCfg) != HAL_OK)
  {
    Error_Handler();
  }
  if (HAL_HRTIM_DeadTimeConfig(&hhrtim1, HRTIM_TIMERINDEX_TIMER_B, &pDeadTimeCfg) != HAL_OK)
  {
    Error_Handler();
  }
  if (HAL_HRTIM_DeadTimeConfig(&hhrtim1, HRTIM_TIMERINDEX_TIMER_C, &pDeadTimeCfg) != HAL_OK)
  {
    Error_Handler();
  }
  pOutputCfg.Polarity = HRTIM_OUTPUTPOLARITY_HIGH;
  pOutputCfg.SetSource = HRTIM_OUTPUTSET_NONE;
  pOutputCfg.ResetSource = HRTIM_OUTPUTRESET_TIMCMP1;
  pOutputCfg.IdleMode = HRTIM_OUTPUTIDLEMODE_NONE;
  pOutputCfg.IdleLevel = HRTIM_OUTPUTIDLELEVEL_INACTIVE;
  pOutputCfg.FaultLevel = HRTIM_OUTPUTFAULTLEVEL_INACTIVE;
  pOutputCfg.ChopperModeEnable = HRTIM_OUTPUTCHOPPERMODE_DISABLED;
  pOutputCfg.BurstModeEntryDelayed = HRTIM_OUTPUTBURSTMODEENTRY_REGULAR;
  if (HAL_HRTIM_WaveformOutputConfig(&hhrtim1, HRTIM_TIMERINDEX_TIMER_A, HRTIM_OUTPUT_TA1, &pOutputCfg) != HAL_OK)
  {
    Error_Handler();
  }
  if (HAL_HRTIM_WaveformOutputConfig(&hhrtim1, HRTIM_TIMERINDEX_TIMER_B, HRTIM_OUTPUT_TB1, &pOutputCfg) != HAL_OK)
  {
    Error_Handler();
  }
  if (HAL_HRTIM_WaveformOutputConfig(&hhrtim1, HRTIM_TIMERINDEX_TIMER_C, HRTIM_OUTPUT_TC1, &pOutputCfg) != HAL_OK)
  {
    Error_Handler();
  }
  pOutputCfg.ResetSource = HRTIM_OUTPUTRESET_NONE;
  if (HAL_HRTIM_WaveformOutputConfig(&hhrtim1, HRTIM_TIMERINDEX_TIMER_A, HRTIM_OUTPUT_TA2, &pOutputCfg) != HAL_OK)
  {
    Error_Handler();
  }
  if (HAL_HRTIM_WaveformOutputConfig(&hhrtim1, HRTIM_TIMERINDEX_TIMER_B, HRTIM_OUTPUT_TB2, &pOutputCfg) != HAL_OK)
  {
    Error_Handler();
  }
  if (HAL_HRTIM_WaveformOutputConfig(&hhrtim1, HRTIM_TIMERINDEX_TIMER_C, HRTIM_OUTPUT_TC2, &pOutputCfg) != HAL_OK)
  {
    Error_Handler();
  }
  if (HAL_HRTIM_TimeBaseConfig(&hhrtim1, HRTIM_TIMERINDEX_TIMER_B, &pTimeBaseCfg) != HAL_OK)
  {
    Error_Handler();
  }
  if (HAL_HRTIM_WaveformTimerControl(&hhrtim1, HRTIM_TIMERINDEX_TIMER_B, &pTimerCtl) != HAL_OK)
  {
    Error_Handler();
  }
  if (HAL_HRTIM_RollOverModeConfig(&hhrtim1, HRTIM_TIMERINDEX_TIMER_B, HRTIM_TIM_FEROM_BOTH|HRTIM_TIM_BMROM_BOTH
                              |HRTIM_TIM_ADROM_BOTH|HRTIM_TIM_OUTROM_BOTH
                              |HRTIM_TIM_ROM_BOTH) != HAL_OK)
  {
    Error_Handler();
  }
  pCompareCfg.CompareValue = HRTIM_PERIOD/2;
  if (HAL_HRTIM_WaveformCompareConfig(&hhrtim1, HRTIM_TIMERINDEX_TIMER_B, HRTIM_COMPAREUNIT_1, &pCompareCfg) != HAL_OK)
  {
    Error_Handler();
  }
  if (HAL_HRTIM_TimeBaseConfig(&hhrtim1, HRTIM_TIMERINDEX_TIMER_C, &pTimeBaseCfg) != HAL_OK)
  {
    Error_Handler();
  }
  if (HAL_HRTIM_WaveformTimerControl(&hhrtim1, HRTIM_TIMERINDEX_TIMER_C, &pTimerCtl) != HAL_OK)
  {
    Error_Handler();
  }
  if (HAL_HRTIM_RollOverModeConfig(&hhrtim1, HRTIM_TIMERINDEX_TIMER_C, HRTIM_TIM_FEROM_BOTH|HRTIM_TIM_BMROM_BOTH
                              |HRTIM_TIM_ADROM_BOTH|HRTIM_TIM_OUTROM_BOTH
                              |HRTIM_TIM_ROM_BOTH) != HAL_OK)
  {
    Error_Handler();
  }
  pCompareCfg.CompareValue = (HRTIM_PERIOD/2);
  if (HAL_HRTIM_WaveformCompareConfig(&hhrtim1, HRTIM_TIMERINDEX_TIMER_C, HRTIM_COMPAREUNIT_1, &pCompareCfg) != HAL_OK)
  {
    Error_Handler();
  }
  HAL_HRTIM_MspPostInit(&hhrtim1);

}

static void MX_I2C1_Init(void)
{

  hi2c1.Instance = I2C1;
  hi2c1.Init.Timing = 0x30A0A7FB;
  hi2c1.Init.OwnAddress1 = 0;
  hi2c1.Init.AddressingMode = I2C_ADDRESSINGMODE_7BIT;
  hi2c1.Init.DualAddressMode = I2C_DUALADDRESS_DISABLE;
  hi2c1.Init.OwnAddress2 = 0;
  hi2c1.Init.OwnAddress2Masks = I2C_OA2_NOMASK;
  hi2c1.Init.GeneralCallMode = I2C_GENERALCALL_DISABLE;
  hi2c1.Init.NoStretchMode = I2C_NOSTRETCH_DISABLE;
  if (HAL_I2C_Init(&hi2c1) != HAL_OK)
  {
    Error_Handler();
  }

  /** Configure Analogue filter
  */
  if (HAL_I2CEx_ConfigAnalogFilter(&hi2c1, I2C_ANALOGFILTER_ENABLE) != HAL_OK)
  {
    Error_Handler();
  }

  /** Configure Digital filter
  */
  if (HAL_I2CEx_ConfigDigitalFilter(&hi2c1, 0) != HAL_OK)
  {
    Error_Handler();
  }

}

static void MX_IWDG_Init(void)
{

  hiwdg.Instance = IWDG;
  hiwdg.Init.Prescaler = IWDG_PRESCALER_4;
  hiwdg.Init.Window = 4095;
  hiwdg.Init.Reload = 4095;
  if (HAL_IWDG_Init(&hiwdg) != HAL_OK)
  {
    Error_Handler();
  }

}

static void MX_LPUART1_UART_Init(void)
{

  hlpuart1.Instance = LPUART1;
  hlpuart1.Init.BaudRate = 115200;
  hlpuart1.Init.WordLength = UART_WORDLENGTH_8B;
  hlpuart1.Init.StopBits = UART_STOPBITS_1;
  hlpuart1.Init.Parity = UART_PARITY_NONE;
  hlpuart1.Init.Mode = UART_MODE_TX_RX;
  hlpuart1.Init.HwFlowCtl = UART_HWCONTROL_NONE;
  hlpuart1.Init.OneBitSampling = UART_ONE_BIT_SAMPLE_DISABLE;
  hlpuart1.Init.ClockPrescaler = UART_PRESCALER_DIV1;
  hlpuart1.AdvancedInit.AdvFeatureInit = UART_ADVFEATURE_NO_INIT;
  if (HAL_UART_Init(&hlpuart1) != HAL_OK)
  {
    Error_Handler();
  }
  if (HAL_UARTEx_SetTxFifoThreshold(&hlpuart1, UART_TXFIFO_THRESHOLD_1_2) != HAL_OK)
  {
    Error_Handler();
  }
  if (HAL_UARTEx_SetRxFifoThreshold(&hlpuart1, UART_RXFIFO_THRESHOLD_1_2) != HAL_OK)
  {
    Error_Handler();
  }
  if (HAL_UARTEx_EnableFifoMode(&hlpuart1) != HAL_OK)
  {
    Error_Handler();
  }

}

static void MX_USART1_UART_Init(void)
{

  huart1.Instance = USART1;
  huart1.Init.BaudRate = 115200;
  huart1.Init.WordLength = UART_WORDLENGTH_8B;
  huart1.Init.StopBits = UART_STOPBITS_1;
  huart1.Init.Parity = UART_PARITY_NONE;
  huart1.Init.Mode = UART_MODE_TX_RX;
  huart1.Init.HwFlowCtl = UART_HWCONTROL_NONE;
  huart1.Init.OverSampling = UART_OVERSAMPLING_16;
  huart1.Init.OneBitSampling = UART_ONE_BIT_SAMPLE_DISABLE;
  huart1.Init.ClockPrescaler = UART_PRESCALER_DIV1;
  huart1.AdvancedInit.AdvFeatureInit = UART_ADVFEATURE_NO_INIT;
  if (HAL_UART_Init(&huart1) != HAL_OK)
  {
    Error_Handler();
  }
  if (HAL_UARTEx_SetTxFifoThreshold(&huart1, UART_TXFIFO_THRESHOLD_1_8) != HAL_OK)
  {
    Error_Handler();
  }
  if (HAL_UARTEx_SetRxFifoThreshold(&huart1, UART_RXFIFO_THRESHOLD_1_8) != HAL_OK)
  {
    Error_Handler();
  }
  if (HAL_UARTEx_DisableFifoMode(&huart1) != HAL_OK)
  {
    Error_Handler();
  }

}

static void MX_USART3_UART_Init(void)
{

  huart3.Instance = USART3;
  huart3.Init.BaudRate = 115200;
  huart3.Init.WordLength = UART_WORDLENGTH_8B;
  huart3.Init.StopBits = UART_STOPBITS_1;
  huart3.Init.Parity = UART_PARITY_NONE;
  huart3.Init.Mode = UART_MODE_TX_RX;
  huart3.Init.HwFlowCtl = UART_HWCONTROL_NONE;
  huart3.Init.OverSampling = UART_OVERSAMPLING_16;
  huart3.Init.OneBitSampling = UART_ONE_BIT_SAMPLE_DISABLE;
  huart3.Init.ClockPrescaler = UART_PRESCALER_DIV1;
  huart3.AdvancedInit.AdvFeatureInit = UART_ADVFEATURE_NO_INIT;
  if (HAL_UART_Init(&huart3) != HAL_OK)
  {
    Error_Handler();
  }
  if (HAL_UARTEx_SetTxFifoThreshold(&huart3, UART_TXFIFO_THRESHOLD_1_8) != HAL_OK)
  {
    Error_Handler();
  }
  if (HAL_UARTEx_SetRxFifoThreshold(&huart3, UART_RXFIFO_THRESHOLD_1_8) != HAL_OK)
  {
    Error_Handler();
  }
  if (HAL_UARTEx_DisableFifoMode(&huart3) != HAL_OK)
  {
    Error_Handler();
  }

}

static void MX_SPI1_Init(void)
{

  LL_SPI_InitTypeDef SPI_InitStruct = {0};

  LL_GPIO_InitTypeDef GPIO_InitStruct = {0};

  /* Peripheral clock enable */
  LL_APB2_GRP1_EnableClock(LL_APB2_GRP1_PERIPH_SPI1);

  LL_AHB2_GRP1_EnableClock(LL_AHB2_GRP1_PERIPH_GPIOA);
  LL_AHB2_GRP1_EnableClock(LL_AHB2_GRP1_PERIPH_GPIOB);
  /**SPI1 GPIO Configuration
  PA15   ------> SPI1_NSS
  PB3   ------> SPI1_SCK
  PB4   ------> SPI1_MISO
  */
  GPIO_InitStruct.Pin = LL_GPIO_PIN_15;
  GPIO_InitStruct.Mode = LL_GPIO_MODE_ALTERNATE;
  GPIO_InitStruct.Speed = LL_GPIO_SPEED_FREQ_LOW;
  GPIO_InitStruct.OutputType = LL_GPIO_OUTPUT_PUSHPULL;
  GPIO_InitStruct.Pull = LL_GPIO_PULL_NO;
  GPIO_InitStruct.Alternate = LL_GPIO_AF_5;
  LL_GPIO_Init(GPIOA, &GPIO_InitStruct);

  GPIO_InitStruct.Pin = LL_GPIO_PIN_3;
  GPIO_InitStruct.Mode = LL_GPIO_MODE_ALTERNATE;
  GPIO_InitStruct.Speed = LL_GPIO_SPEED_FREQ_LOW;
  GPIO_InitStruct.OutputType = LL_GPIO_OUTPUT_PUSHPULL;
  GPIO_InitStruct.Pull = LL_GPIO_PULL_NO;
  GPIO_InitStruct.Alternate = LL_GPIO_AF_5;
  LL_GPIO_Init(GPIOB, &GPIO_InitStruct);

  GPIO_InitStruct.Pin = LL_GPIO_PIN_4;
  GPIO_InitStruct.Mode = LL_GPIO_MODE_ALTERNATE;
  GPIO_InitStruct.Speed = LL_GPIO_SPEED_FREQ_LOW;
  GPIO_InitStruct.OutputType = LL_GPIO_OUTPUT_PUSHPULL;
  GPIO_InitStruct.Pull = LL_GPIO_PULL_NO;
  GPIO_InitStruct.Alternate = LL_GPIO_AF_5;
  LL_GPIO_Init(GPIOB, &GPIO_InitStruct);

  /* SPI1 interrupt Init */
  NVIC_SetPriority(SPI1_IRQn, NVIC_EncodePriority(NVIC_GetPriorityGrouping(),6, 0));
  NVIC_EnableIRQ(SPI1_IRQn);

  /* SPI1 parameter configuration*/
  SPI_InitStruct.TransferDirection = LL_SPI_SIMPLEX_RX;
  SPI_InitStruct.Mode = LL_SPI_MODE_MASTER;
  SPI_InitStruct.DataWidth = LL_SPI_DATAWIDTH_16BIT;
  SPI_InitStruct.ClockPolarity = LL_SPI_POLARITY_LOW;
  SPI_InitStruct.ClockPhase = LL_SPI_PHASE_1EDGE;
  SPI_InitStruct.NSS = LL_SPI_NSS_HARD_OUTPUT;
  SPI_InitStruct.BaudRate = LL_SPI_BAUDRATEPRESCALER_DIV8;
  SPI_InitStruct.BitOrder = LL_SPI_MSB_FIRST;
  SPI_InitStruct.CRCCalculation = LL_SPI_CRCCALCULATION_DISABLE;
  SPI_InitStruct.CRCPoly = 7;
  LL_SPI_Init(SPI1, &SPI_InitStruct);
  LL_SPI_SetStandard(SPI1, LL_SPI_PROTOCOL_MOTOROLA);
  LL_SPI_EnableNSSPulseMgt(SPI1);

}

static void MX_TIM2_Init(void)
{

  TIM_Encoder_InitTypeDef sConfig = {0};
  TIM_MasterConfigTypeDef sMasterConfig = {0};
  TIM_IC_InitTypeDef sConfigIC = {0};
  TIMEx_EncoderIndexConfigTypeDef sEncoderIndexConfig = {0};

  htim2.Instance = TIM2;
  htim2.Init.Prescaler = 0;
  htim2.Init.CounterMode = TIM_COUNTERMODE_UP;
  htim2.Init.Period = 2047;
  htim2.Init.ClockDivision = TIM_CLOCKDIVISION_DIV1;
  htim2.Init.AutoReloadPreload = TIM_AUTORELOAD_PRELOAD_DISABLE;
  if (HAL_TIM_IC_Init(&htim2) != HAL_OK)
  {
    Error_Handler();
  }
  sConfig.EncoderMode = TIM_ENCODERMODE_TI1;
  sConfig.IC1Polarity = TIM_ICPOLARITY_RISING;
  sConfig.IC1Selection = TIM_ICSELECTION_DIRECTTI;
  sConfig.IC1Prescaler = TIM_ICPSC_DIV1;
  sConfig.IC1Filter = 0;
  sConfig.IC2Polarity = TIM_ICPOLARITY_RISING;
  sConfig.IC2Selection = TIM_ICSELECTION_DIRECTTI;
  sConfig.IC2Prescaler = TIM_ICPSC_DIV1;
  sConfig.IC2Filter = 0;
  if (HAL_TIM_Encoder_Init(&htim2, &sConfig) != HAL_OK)
  {
    Error_Handler();
  }
  sMasterConfig.MasterOutputTrigger = TIM_TRGO_RESET;
  sMasterConfig.MasterSlaveMode = TIM_MASTERSLAVEMODE_DISABLE;
  if (HAL_TIMEx_MasterConfigSynchronization(&htim2, &sMasterConfig) != HAL_OK)
  {
    Error_Handler();
  }
  sConfigIC.ICPolarity = TIM_INPUTCHANNELPOLARITY_RISING;
  sConfigIC.ICSelection = TIM_ICSELECTION_DIRECTTI;
  sConfigIC.ICPrescaler = TIM_ICPSC_DIV1;
  sConfigIC.ICFilter = 0;
  if (HAL_TIM_IC_ConfigChannel(&htim2, &sConfigIC, TIM_CHANNEL_3) != HAL_OK)
  {
    Error_Handler();
  }
  sEncoderIndexConfig.Polarity = TIM_ENCODERINDEX_POLARITY_NONINVERTED;
  sEncoderIndexConfig.Prescaler = TIM_ENCODERINDEX_PRESCALER_DIV1;
  sEncoderIndexConfig.Filter = 0;
  sEncoderIndexConfig.FirstIndexEnable = DISABLE;
  sEncoderIndexConfig.Position = TIM_ENCODERINDEX_POSITION_10;
  sEncoderIndexConfig.Direction = TIM_ENCODERINDEX_DIRECTION_UP_DOWN;
  if (HAL_TIMEx_ConfigEncoderIndex(&htim2, &sEncoderIndexConfig) != HAL_OK)
  {
    Error_Handler();
  }

}

static void MX_TIM3_Init(void)
{

  TIM_Encoder_InitTypeDef sConfig = {0};
  TIM_MasterConfigTypeDef sMasterConfig = {0};
  TIM_IC_InitTypeDef sConfigIC = {0};
  TIMEx_EncoderIndexConfigTypeDef sEncoderIndexConfig = {0};

  htim3.Instance = TIM3;
  htim3.Init.Prescaler = 0;
  htim3.Init.CounterMode = TIM_COUNTERMODE_UP;
  htim3.Init.Period = 65535;
  htim3.Init.ClockDivision = TIM_CLOCKDIVISION_DIV1;
  htim3.Init.AutoReloadPreload = TIM_AUTORELOAD_PRELOAD_DISABLE;
  if (HAL_TIM_IC_Init(&htim3) != HAL_OK)
  {
    Error_Handler();
  }
  sConfig.EncoderMode = TIM_ENCODERMODE_TI1;
  sConfig.IC1Polarity = TIM_ICPOLARITY_RISING;
  sConfig.IC1Selection = TIM_ICSELECTION_DIRECTTI;
  sConfig.IC1Prescaler = TIM_ICPSC_DIV1;
  sConfig.IC1Filter = 0;
  sConfig.IC2Polarity = TIM_ICPOLARITY_RISING;
  sConfig.IC2Selection = TIM_ICSELECTION_DIRECTTI;
  sConfig.IC2Prescaler = TIM_ICPSC_DIV1;
  sConfig.IC2Filter = 0;
  if (HAL_TIM_Encoder_Init(&htim3, &sConfig) != HAL_OK)
  {
    Error_Handler();
  }
  sMasterConfig.MasterOutputTrigger = TIM_TRGO_RESET;
  sMasterConfig.MasterSlaveMode = TIM_MASTERSLAVEMODE_DISABLE;
  if (HAL_TIMEx_MasterConfigSynchronization(&htim3, &sMasterConfig) != HAL_OK)
  {
    Error_Handler();
  }
  sConfigIC.ICPolarity = TIM_INPUTCHANNELPOLARITY_RISING;
  sConfigIC.ICSelection = TIM_ICSELECTION_DIRECTTI;
  sConfigIC.ICPrescaler = TIM_ICPSC_DIV1;
  sConfigIC.ICFilter = 0;
  if (HAL_TIM_IC_ConfigChannel(&htim3, &sConfigIC, TIM_CHANNEL_3) != HAL_OK)
  {
    Error_Handler();
  }
  sEncoderIndexConfig.Polarity = TIM_ENCODERINDEX_POLARITY_NONINVERTED;
  sEncoderIndexConfig.Prescaler = TIM_ENCODERINDEX_PRESCALER_DIV1;
  sEncoderIndexConfig.Filter = 0;
  sEncoderIndexConfig.FirstIndexEnable = DISABLE;
  sEncoderIndexConfig.Position = TIM_ENCODERINDEX_POSITION_00;
  sEncoderIndexConfig.Direction = TIM_ENCODERINDEX_DIRECTION_UP_DOWN;
  if (HAL_TIMEx_ConfigEncoderIndex(&htim3, &sEncoderIndexConfig) != HAL_OK)
  {
    Error_Handler();
  }

}

static void MX_DMA_Init(void)
{

  /* DMA controller clock enable */
  __HAL_RCC_DMAMUX1_CLK_ENABLE();
  __HAL_RCC_DMA1_CLK_ENABLE();

  /* DMA interrupt init */
  /* DMA1_Channel1_IRQn interrupt configuration */
  HAL_NVIC_SetPriority(DMA1_Channel1_IRQn, 10, 0);
  HAL_NVIC_EnableIRQ(DMA1_Channel1_IRQn);

}

static void MX_GPIO_Init(void)
{
  GPIO_InitTypeDef GPIO_InitStruct = {0};

  /* GPIO Ports Clock Enable */
  __HAL_RCC_GPIOC_CLK_ENABLE();
  __HAL_RCC_GPIOF_CLK_ENABLE();
  __HAL_RCC_GPIOA_CLK_ENABLE();
  __HAL_RCC_GPIOB_CLK_ENABLE();
  __HAL_RCC_GPIOD_CLK_ENABLE();

  /*Configure GPIO pin Output Level */
  HAL_GPIO_WritePin(GPIOA, GPIO_PIN_6, GPIO_PIN_RESET);

  /*Configure GPIO pin Output Level */
  HAL_GPIO_WritePin(GPIOB, GPIO_PIN_14|GPIO_PIN_15|GPIO_PIN_5, GPIO_PIN_RESET);

  /*Configure GPIO pin Output Level */
  HAL_GPIO_WritePin(ERR_CLEAR_GPIO_Port, ERR_CLEAR_Pin, GPIO_PIN_RESET);

  /*Configure GPIO pin : BUTTON_Pin */
  GPIO_InitStruct.Pin = BUTTON_Pin;
  GPIO_InitStruct.Mode = GPIO_MODE_INPUT;
  GPIO_InitStruct.Pull = GPIO_NOPULL;
  HAL_GPIO_Init(BUTTON_GPIO_Port, &GPIO_InitStruct);

  /*Configure GPIO pin : PA6 */
  GPIO_InitStruct.Pin = GPIO_PIN_6;
  GPIO_InitStruct.Mode = GPIO_MODE_OUTPUT_PP;
  GPIO_InitStruct.Pull = GPIO_NOPULL;
  GPIO_InitStruct.Speed = GPIO_SPEED_FREQ_LOW;
  HAL_GPIO_Init(GPIOA, &GPIO_InitStruct);

  /*Configure GPIO pin : PB11 */
  GPIO_InitStruct.Pin = GPIO_PIN_11;
  GPIO_InitStruct.Mode = GPIO_MODE_INPUT;
  GPIO_InitStruct.Pull = GPIO_NOPULL;
  HAL_GPIO_Init(GPIOB, &GPIO_InitStruct);

  /*Configure GPIO pins : PB14 PB15 PB5 */
  GPIO_InitStruct.Pin = GPIO_PIN_14|GPIO_PIN_15|GPIO_PIN_5;
  GPIO_InitStruct.Mode = GPIO_MODE_OUTPUT_PP;
  GPIO_InitStruct.Pull = GPIO_NOPULL;
  GPIO_InitStruct.Speed = GPIO_SPEED_FREQ_LOW;
  HAL_GPIO_Init(GPIOB, &GPIO_InitStruct);

  /*Configure GPIO pin : ERR_CLEAR_Pin */
  GPIO_InitStruct.Pin = ERR_CLEAR_Pin;
  GPIO_InitStruct.Mode = GPIO_MODE_OUTPUT_PP;
  GPIO_InitStruct.Pull = GPIO_NOPULL;
  GPIO_InitStruct.Speed = GPIO_SPEED_FREQ_LOW;
  HAL_GPIO_Init(ERR_CLEAR_GPIO_Port, &GPIO_InitStruct);

}

void Error_Handler(void)
{
  __disable_irq();
  while (1)
  {
  }
}
